# nrf52811 register map
Vendor: Nordic Semiconductor; Series: nrf52; File version: 1
CPU: CM4 r0p1, little endian, MPU, no FPU, 3 interrupt priority bits
Registers are 32-bit, read-write, reset 0x0 unless marked. A register's access mark holds for its fields unless they carry their own. Offsets are from the block's base; [hi:lo] are bit positions; lines under a group give offsets from that group; {n}, {i} and the like mark numbered series.

## EGU0 — Event Generator Unit 0
Base 0x40014000
Same registers: EGU1 0x40015000
{0x0+4i} TASKS_TRIGGER[{i}] (i=0..15) wo — Description collection: Trigger n for triggering the corresponding TRIGGERED[n] event
  [0] TASKS_TRIGGER — Trigger n for triggering the corresponding TRIGGERED[n] event
    1=Trigger task
{0x100+4i} EVENTS_TRIGGERED[{i}] (i=0..15) — Description collection: Event number n generated by triggering the corresponding TRIGGER[n] task
  [0] EVENTS_TRIGGERED — Event number n generated by triggering the corresponding TRIGGER[n] task
    0=NotGenerated (Event not generated); 1=Generated (Event generated)
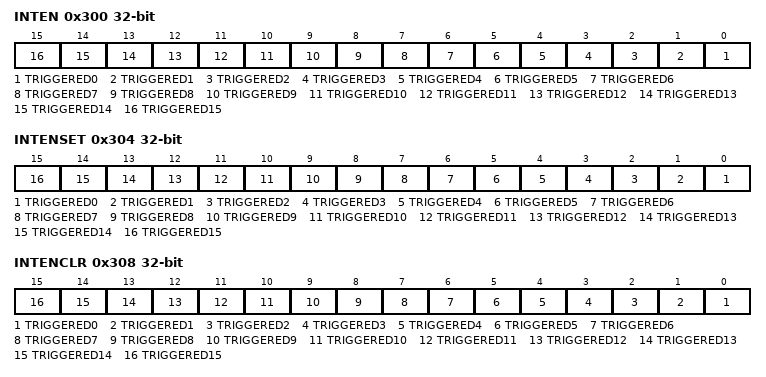
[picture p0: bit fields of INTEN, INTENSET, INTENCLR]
0x300 INTEN — Enable or disable interrupt
  [all] fields
    0=Disabled; 1=Enabled
  [n] TRIGGERED{n} (n=0..15) — Enable or disable interrupt for event TRIGGERED[{n}]
0x304 INTENSET — Enable interrupt
  [all] fields
    on read: 0=Disabled (Read: Disabled); 1=Enabled (Read: Enabled) | on write: 1=Set (Enable)
  [n] TRIGGERED{n} (n=0..15) — Write '1' to enable interrupt for event TRIGGERED[{n}]
0x308 INTENCLR — Disable interrupt
  [all] fields
    on read: 0=Disabled (Read: Disabled); 1=Enabled (Read: Enabled) | on write: 1=Clear (Disable)
  [n] TRIGGERED{n} (n=0..15) — Write '1' to disable interrupt for event TRIGGERED[{n}]

## SWI0 — Software interrupt 0
Base 0x40014000; alternate view of EGU0
Same registers: SWI1 0x40015000 (alternate view of EGU1), SWI2 0x40016000, SWI3 0x40017000, SWI4 0x40018000, SWI5 0x40019000

## NVMC — Non-volatile memory controller
Base 0x4001E000
0x400 READY ro reset 0x1 — Ready flag
  [0] READY — NVMC is ready or busy
    0=Busy (NVMC is busy (ongoing write or erase operation)); 1=Ready (NVMC is ready)
0x504 CONFIG — Configuration register
  [1:0] WEN — Program memory access mode. It is strongly recommended to activate erase and write modes only when they are actively used.
    0=Ren (Read only access); 1=Wen (Write enabled); 2=Een (Erase enabled)
0x508 ERASEPAGE — Register for erasing a page in code area
  [31:0] ERASEPAGE — Register for starting erase of a page in code area.
0x508 ERASEPCR1 (alternate view of ERASEPAGE) — Deprecated register - Register for erasing a page in code area. Equivalent to ERASEPAGE.
  [31:0] ERASEPCR1 — Register for erasing a page in code area. Equivalent to ERASEPAGE.
0x50C ERASEALL — Register for erasing all non-volatile user memory
  [0] ERASEALL — Erase all non-volatile memory including UICR registers. Note that the erase must be enabled using CONFIG.WEN before the non-volatile memory can be erased.
    0=NoOperation; 1=Erase (Start erase of chip)
0x510 ERASEPCR0 — Deprecated register - Register for erasing a page in code area. Equivalent to ERASEPAGE.
  [31:0] ERASEPCR0 — Register for starting erase of a page in code area. Equivalent to ERASEPAGE.
0x514 ERASEUICR — Register for erasing user information configuration registers
  [0] ERASEUICR — Register starting erase of all user information configuration registers. Note that the erase must be enabled using CONFIG.WEN before the UICR can be erased.
    0=NoOperation; 1=Erase (Start erase of UICR)
0x518 ERASEPAGEPARTIAL — Register for partial erase of a page in code area
  [31:0] ERASEPAGEPARTIAL — Register for starting partial erase of a page in code area
0x51C ERASEPAGEPARTIALCFG reset 0xA — Register for partial erase configuration
  [6:0] DURATION — Duration of the partial erase in milliseconds

## PPI — Programmable Peripheral Interconnect
Base 0x4001F000
{0x0+8i} TASKS_CHG[{i}] (i=0..5) group — Channel group tasks
  0x00 EN wo — Description cluster: Enable channel group n
    [0] EN — Enable channel group n
      1=Trigger task
  0x04 DIS wo — Description cluster: Disable channel group n
    [0] DIS — Disable channel group n
      1=Trigger task
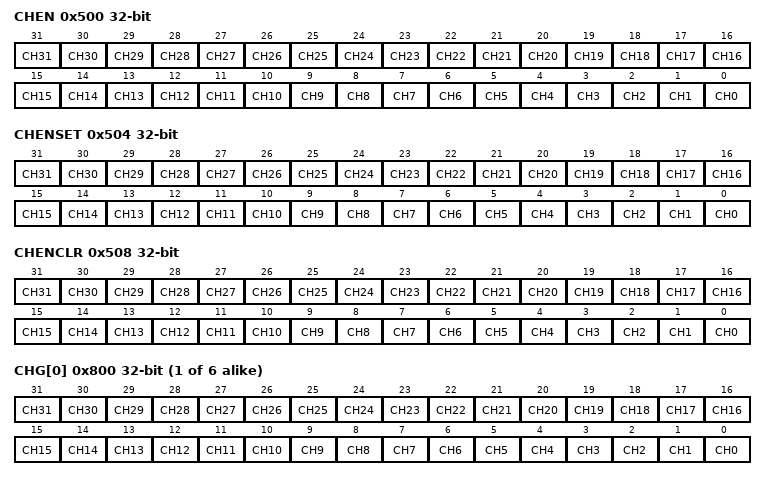
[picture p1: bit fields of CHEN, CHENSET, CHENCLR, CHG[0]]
0x500 CHEN — Channel enable register
  [all] fields
    0=Disabled (Disable channel); 1=Enabled (Enable channel)
  [n] CH{n} (n=0..31) — Enable or disable channel {n}
0x504 CHENSET write-1-sets — Channel enable set register
  [all] fields
    on read: 0=Disabled (Read: channel disabled); 1=Enabled (Read: channel enabled) | on write: 1=Set (Write: Enable channel)
  [n] CH{n} (n=0..31) — Channel {n} enable set register. Writing '0' has no effect
0x508 CHENCLR write-1-clears — Channel enable clear register
  [all] fields
    on read: 0=Disabled (Read: channel disabled); 1=Enabled (Read: channel enabled) | on write: 1=Clear (Write: disable channel)
  [n] CH{n} (n=0..31) — Channel {n} enable clear register. Writing '0' has no effect
{0x510+8i} CH[{i}] (i=0..19) group — PPI Channel
  0x00 EEP — Description cluster: Channel n event end-point
    [31:0] EEP — Pointer to event register. Accepts only addresses to registers from the Event group.
  0x04 TEP — Description cluster: Channel n task end-point
    [31:0] TEP — Pointer to task register. Accepts only addresses to registers from the Task group.
{0x800+4i} CHG[{i}] (i=0..5) — Description collection: Channel group n
  [all] fields
    0=Excluded; 1=Included
  [n] CH{n} (n=0..31) — Include or exclude channel {n}
{0x910+4i} FORK[{i}] (i=0..31) group
  0x00 TEP — Description cluster: Channel n task end-point
    [31:0] TEP — Pointer to task register

## Notices in the file
Copyright (c) 2010 - 2018, Nordic Semiconductor ASA All rights reserved.
Redistribution and use in source and binary forms, with or without
modification, are permitted provided that the following conditions are met:
1. Redistributions of source code must retain the above copyright notice, this
list of conditions and the following disclaimer.
2. Redistributions in binary form must reproduce the above copyright
notice, this list of conditions and the following disclaimer in the
documentation and/or other materials provided with the distribution.
3. Neither the name of Nordic Semiconductor ASA nor the names of its
contributors may be used to endorse or promote products derived from this
software without specific prior written permission.
THIS SOFTWARE IS PROVIDED BY THE COPYRIGHT HOLDERS AND CONTRIBUTORS "AS IS"
AND ANY EXPRESS OR IMPLIED WARRANTIES, INCLUDING, BUT NOT LIMITED TO, THE
IMPLIED WARRANTIES OF MERCHANTABILITY, AND FITNESS FOR A PARTICULAR PURPOSE
ARE DISCLAIMED. IN NO EVENT SHALL NORDIC SEMICONDUCTOR ASA OR CONTRIBUTORS BE
LIABLE FOR ANY DIRECT, INDIRECT, INCIDENTAL, SPECIAL, EXEMPLARY, OR
CONSEQUENTIAL DAMAGES (INCLUDING, BUT NOT LIMITED TO, PROCUREMENT OF
SUBSTITUTE GOODS OR SERVICES; LOSS OF USE, DATA, OR PROFITS; OR BUSINESS
INTERRUPTION) HOWEVER CAUSED AND ON ANY THEORY OF LIABILITY, WHETHER IN
CONTRACT, STRICT LIABILITY, OR TORT (INCLUDING NEGLIGENCE OR OTHERWISE)
ARISING IN ANY WAY OUT OF THE USE OF THIS SOFTWARE, EVEN IF ADVISED OF THE
POSSIBILITY OF SUCH DAMAGE.
